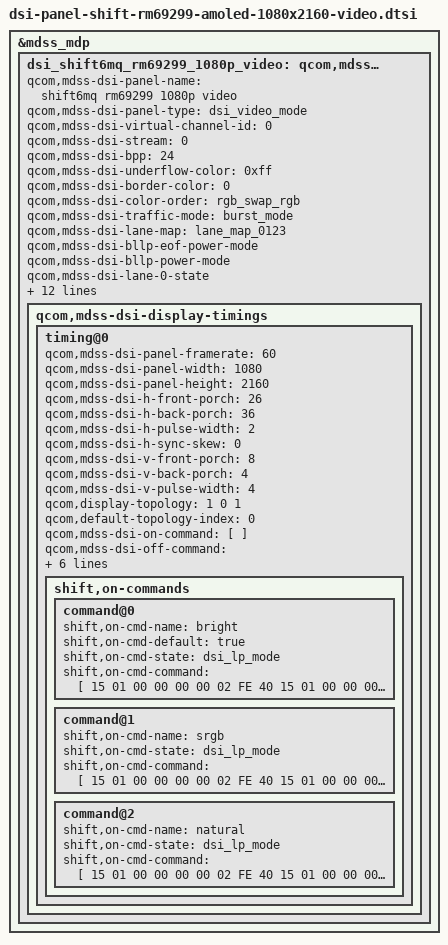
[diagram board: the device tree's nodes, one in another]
/* Copyright (c) 2016-2017, The Linux Foundation. All rights reserved.
 *
 * This program is free software; you can redistribute it and/or modify
 * it under the terms of the GNU General Public License version 2 and
 * only version 2 as published by the Free Software Foundation.
 *
 * This program is distributed in the hope that it will be useful,
 * but WITHOUT ANY WARRANTY; without even the implied warranty of
 * MERCHANTABILITY or FITNESS FOR A PARTICULAR PURPOSE.  See the
 * GNU General Public License for more details.
 */

&mdss_mdp {
	dsi_shift6mq_rm69299_1080p_video: qcom,mdss_dsi_shift6mq_rm69299_1080p_video {
		qcom,mdss-dsi-panel-name =
			"shift6mq rm69299 1080p video";
		qcom,mdss-dsi-panel-type = "dsi_video_mode";
		qcom,mdss-dsi-virtual-channel-id = <0>;
		qcom,mdss-dsi-stream = <0>;
		qcom,mdss-dsi-bpp = <24>;
                qcom,mdss-dsi-underflow-color = <0xff>;
		qcom,mdss-dsi-border-color = <0>;
		qcom,mdss-dsi-color-order = "rgb_swap_rgb"; 
		qcom,mdss-dsi-traffic-mode = "burst_mode";
		qcom,mdss-dsi-lane-map = "lane_map_0123"; 
		qcom,mdss-dsi-bllp-eof-power-mode;
		qcom,mdss-dsi-bllp-power-mode;
		qcom,mdss-dsi-lane-0-state;
		qcom,mdss-dsi-lane-1-state;
		qcom,mdss-dsi-lane-2-state;
		qcom,mdss-dsi-lane-3-state;
		qcom,mdss-dsi-force-clock-lane-hs;
		qcom,mdss-dsi-dma-trigger = "trigger_sw";
		qcom,mdss-dsi-mdp-trigger = "none";
                qcom,mdss-dsi-reset-sequence = <1 20>, <0 20>, <1 20>;
		qcom,mdss-pan-physical-width-dimension = <74>;
		qcom,mdss-pan-physical-height-dimension = <131>;
                qcom,mdss-dsi-t-clk-post = <0x0d>;  
                qcom,mdss-dsi-t-clk-pre = <0x2f>; 
		qcom,mdss-dsi-lp11-init; 
		qcom,mdss-dsi-display-timings {
			timing@0{
                                qcom,mdss-dsi-panel-framerate = <60>;
				qcom,mdss-dsi-panel-width = <1080>;
				qcom,mdss-dsi-panel-height = <2160>;
		                qcom,mdss-dsi-h-front-porch = <26>;
		                qcom,mdss-dsi-h-back-porch = <36>;
		                qcom,mdss-dsi-h-pulse-width = <2>;
				qcom,mdss-dsi-h-sync-skew = <0>;
		                qcom,mdss-dsi-v-front-porch = <8>;
		                qcom,mdss-dsi-v-back-porch = <4>;
		                qcom,mdss-dsi-v-pulse-width = <4>;
                                qcom,display-topology = <1 0 1>;
                                qcom,default-topology-index = <0>; 
				qcom,mdss-dsi-on-command = [
				];
				qcom,mdss-dsi-off-command = [05 01 00 00 14 00 02 28 00
			                                     05 01 00 00 78 00 02 10 00];
				qcom,mdss-dsi-on-command-state = "dsi_lp_mode";
				qcom,mdss-dsi-off-command-state = "dsi_hs_mode";  
				qcom,mdss-dsi-h-sync-pulse = <0>;
                                qcom,mdss-dsi-panel-phy-timings = [00 1e 08 08 24 22 08 08 05 03 04 00];
				shift,on-commands {
					command@0 {
						shift,on-cmd-name = "bright";
						shift,on-cmd-default = "true";
						shift,on-cmd-state = "dsi_lp_mode";
						shift,on-cmd-command = [
                                 15 01 00 00 00 00 02 FE 40 
                                 15 01 00 00 00 00 02 05 04 
                                 15 01 00 00 00 00 02 06 08 
                                 15 01 00 00 00 00 02 08 04 
                                 15 01 00 00 00 00 02 09 08           
                                 15 01 00 00 00 00 02 0A 07 
                                 15 01 00 00 00 00 02 0B CC 
                                 15 01 00 00 00 00 02 0C 07 
                                 15 01 00 00 00 00 02 0D 90 
                                 15 01 00 00 00 00 02 0F 87 
                                 15 01 00 00 00 00 02 20 8D 
                                 15 01 00 00 00 00 02 21 8D 
                                 15 01 00 00 00 00 02 24 05 
                                 15 01 00 00 00 00 02 26 05 
                                 15 01 00 00 00 00 02 28 05 
                                 15 01 00 00 00 00 02 2A 05 
                                 15 01 00 00 00 00 02 2D 28 
                                 15 01 00 00 00 00 02 2F 28 
                                 15 01 00 00 00 00 02 30 32 
                                 15 01 00 00 00 00 02 31 32 
                                 15 01 00 00 00 00 02 37 80 
                                 15 01 00 00 00 00 02 38 30 
                                 15 01 00 00 00 00 02 39 A8     
                                 15 01 00 00 00 00 02 46 48
                                 15 01 00 00 00 00 02 47 48 
                                 15 01 00 00 00 00 02 6B 10  
                                 15 01 00 00 00 00 02 6F 02 
                                 15 01 00 00 00 00 02 74 2B /* (AVDD) 7.6V*/
                                 15 01 00 00 00 00 02 80 1A /* (OVSS)  -2.9V*/
                                 15 01 00 00 00 00 02 FE 40 
                                 15 01 00 00 00 00 02 93 10 
                                 15 01 00 00 00 00 02 16 00 
                                 15 01 00 00 00 00 02 85 07 
                                 15 01 00 00 00 00 02 84 01 
                                 15 01 00 00 00 00 02 86 0F 
                                 15 01 00 00 00 00 02 87 05 
                                 15 01 00 00 00 00 02 8C 00 
                                 15 01 00 00 00 00 02 88 2E 
                                 15 01 00 00 00 00 02 89 2E 
                                 15 01 00 00 00 00 02 8B 09 
                                 15 01 00 00 00 00 02 95 00 
                                 15 01 00 00 00 00 02 91 00 
                                 15 01 00 00 00 00 02 90 00 
                                 15 01 00 00 00 00 02 8D D0 
                                 15 01 00 00 00 00 02 8A 03 
                                 15 01 00 00 00 00 02 FE A0 
                                 15 01 00 00 00 00 02 13 00 
                                 15 01 00 00 00 00 02 33 00 
                                 15 01 00 00 00 00 02 0B 33 
                                 15 01 00 00 00 00 02 36 1E 
                                 15 01 00 00 00 00 02 31 88 
                                 15 01 00 00 00 00 02 32 88 
                                 15 01 00 00 00 00 02 37 F1 
                                 15 01 00 00 00 00 02 FE 50
                                 15 01 00 00 00 00 02 00 00 //R0
                                 15 01 00 00 00 00 02 01 00
                                 15 01 00 00 00 00 02 02 00
                                 15 01 00 00 00 00 02 03 E9
                                 15 01 00 00 00 00 02 04 00
                                 15 01 00 00 00 00 02 05 F6
                                 15 01 00 00 00 00 02 06 01
                                 15 01 00 00 00 00 02 07 2C
                                 15 01 00 00 00 00 02 08 01
                                 15 01 00 00 00 00 02 09 62
                                 15 01 00 00 00 00 02 0A 01
                                 15 01 00 00 00 00 02 0B 98
                                 15 01 00 00 00 00 02 0C 01
                                 15 01 00 00 00 00 02 0D BF
                                 15 01 00 00 00 00 02 0E 01
                                 15 01 00 00 00 00 02 0F F6
                                 15 01 00 00 00 00 02 10 02
                                 15 01 00 00 00 00 02 11 24
                                 15 01 00 00 00 00 02 12 02
                                 15 01 00 00 00 00 02 13 4E
                                 15 01 00 00 00 00 02 14 02
                                 15 01 00 00 00 00 02 15 70
                                 15 01 00 00 00 00 02 16 02
                                 15 01 00 00 00 00 02 17 AF
                                 15 01 00 00 00 00 02 18 02
                                 15 01 00 00 00 00 02 19 E2
                                 15 01 00 00 00 00 02 1A 03
                                 15 01 00 00 00 00 02 1B 1F
                                 15 01 00 00 00 00 02 1C 03
                                 15 01 00 00 00 00 02 1D 52
                                 15 01 00 00 00 00 02 1E 03
                                 15 01 00 00 00 00 02 1F 82
                                 15 01 00 00 00 00 02 20 03
                                 15 01 00 00 00 00 02 21 B6
                                 15 01 00 00 00 00 02 22 03
                                 15 01 00 00 00 00 02 23 F0
                                 15 01 00 00 00 00 02 24 04
                                 15 01 00 00 00 00 02 25 1F
                                 15 01 00 00 00 00 02 26 04
                                 15 01 00 00 00 00 02 27 37
                                 15 01 00 00 00 00 02 28 04
                                 15 01 00 00 00 00 02 29 59
                                 15 01 00 00 00 00 02 2A 04
                                 15 01 00 00 00 00 02 2B 68
                                 15 01 00 00 00 00 02 30 04
                                 15 01 00 00 00 00 02 31 85
                                 15 01 00 00 00 00 02 32 04
                                 15 01 00 00 00 00 02 33 A2
                                 15 01 00 00 00 00 02 34 04
                                 15 01 00 00 00 00 02 35 BC
                                 15 01 00 00 00 00 02 36 04
                                 15 01 00 00 00 00 02 37 D8
                                 15 01 00 00 00 00 02 38 04
                                 15 01 00 00 00 00 02 39 F4
                                 15 01 00 00 00 00 02 3A 05
                                 15 01 00 00 00 00 02 3B 0E
                                 15 01 00 00 00 00 02 40 05
                                 15 01 00 00 00 00 02 41 13
                                 15 01 00 00 00 00 02 42 05
                                 15 01 00 00 00 00 02 43 1F
                                 15 01 00 00 00 00 02 44 05
                                 15 01 00 00 00 00 02 45 1F
                                 15 01 00 00 00 00 02 46 00 //G0
                                 15 01 00 00 00 00 02 47 00
                                 15 01 00 00 00 00 02 48 01
                                 15 01 00 00 00 00 02 49 43
                                 15 01 00 00 00 00 02 4A 01
                                 15 01 00 00 00 00 02 4B 4C
                                 15 01 00 00 00 00 02 4C 01
                                 15 01 00 00 00 00 02 4D 6F
                                 15 01 00 00 00 00 02 4E 01
                                 15 01 00 00 00 00 02 4F 92
                                 15 01 00 00 00 00 02 50 01
                                 15 01 00 00 00 00 02 51 B5
                                 15 01 00 00 00 00 02 52 01
                                 15 01 00 00 00 00 02 53 D4
                                 15 01 00 00 00 00 02 58 02
                                 15 01 00 00 00 00 02 59 06
                                 15 01 00 00 00 00 02 5A 02
                                 15 01 00 00 00 00 02 5B 33
                                 15 01 00 00 00 00 02 5C 02
                                 15 01 00 00 00 00 02 5D 59
                                 15 01 00 00 00 00 02 5E 02
                                 15 01 00 00 00 00 02 5F 7D
                                 15 01 00 00 00 00 02 60 02
                                 15 01 00 00 00 00 02 61 BD
                                 15 01 00 00 00 00 02 62 02
                                 15 01 00 00 00 00 02 63 F7
                                 15 01 00 00 00 00 02 64 03
                                 15 01 00 00 00 00 02 65 31
                                 15 01 00 00 00 00 02 66 03
                                 15 01 00 00 00 00 02 67 63
                                 15 01 00 00 00 00 02 68 03
                                 15 01 00 00 00 00 02 69 9D
                                 15 01 00 00 00 00 02 6A 03
                                 15 01 00 00 00 00 02 6B D2
                                 15 01 00 00 00 00 02 6C 04
                                 15 01 00 00 00 00 02 6D 05
                                 15 01 00 00 00 00 02 6E 04
                                 15 01 00 00 00 00 02 6F 38
                                 15 01 00 00 00 00 02 70 04
                                 15 01 00 00 00 00 02 71 51
                                 15 01 00 00 00 00 02 72 04
                                 15 01 00 00 00 00 02 73 70
                                 15 01 00 00 00 00 02 74 04
                                 15 01 00 00 00 00 02 75 85
                                 15 01 00 00 00 00 02 76 04
                                 15 01 00 00 00 00 02 77 A1
                                 15 01 00 00 00 00 02 78 04
                                 15 01 00 00 00 00 02 79 C0
                                 15 01 00 00 00 00 02 7A 04
                                 15 01 00 00 00 00 02 7B D8
                                 15 01 00 00 00 00 02 7C 04
                                 15 01 00 00 00 00 02 7D F2
                                 15 01 00 00 00 00 02 7E 05
                                 15 01 00 00 00 00 02 7F 10
                                 15 01 00 00 00 00 02 80 05
                                 15 01 00 00 00 00 02 81 21
                                 15 01 00 00 00 00 02 82 05
                                 15 01 00 00 00 00 02 83 2E
                                 15 01 00 00 00 00 02 84 05
                                 15 01 00 00 00 00 02 85 3A
                                 15 01 00 00 00 00 02 86 05
                                 15 01 00 00 00 00 02 87 3E
                                 15 01 00 00 00 00 02 88 00 //B0
                                 15 01 00 00 00 00 02 89 00
                                 15 01 00 00 00 00 02 8A 01
                                 15 01 00 00 00 00 02 8B 86
                                 15 01 00 00 00 00 02 8C 01
                                 15 01 00 00 00 00 02 8D 8F
                                 15 01 00 00 00 00 02 8E 01
                                 15 01 00 00 00 00 02 8F B3
                                 15 01 00 00 00 00 02 90 01
                                 15 01 00 00 00 00 02 91 D7
                                 15 01 00 00 00 00 02 92 01
                                 15 01 00 00 00 00 02 93 FB
                                 15 01 00 00 00 00 02 94 02
                                 15 01 00 00 00 00 02 95 18
                                 15 01 00 00 00 00 02 96 02
                                 15 01 00 00 00 00 02 97 4F
                                 15 01 00 00 00 00 02 98 02
                                 15 01 00 00 00 00 02 99 7E
                                 15 01 00 00 00 00 02 9A 02
                                 15 01 00 00 00 00 02 9B A6
                                 15 01 00 00 00 00 02 9C 02
                                 15 01 00 00 00 00 02 9D CF
                                 15 01 00 00 00 00 02 9E 03
                                 15 01 00 00 00 00 02 9F 14
                                 15 01 00 00 00 00 02 A4 03
                                 15 01 00 00 00 00 02 A5 52
                                 15 01 00 00 00 00 02 A6 03
                                 15 01 00 00 00 00 02 A7 93
                                 15 01 00 00 00 00 02 AC 03
                                 15 01 00 00 00 00 02 AD CF
                                 15 01 00 00 00 00 02 AE 04
                                 15 01 00 00 00 00 02 AF 08
                                 15 01 00 00 00 00 02 B0 04
                                 15 01 00 00 00 00 02 B1 42
                                 15 01 00 00 00 00 02 B2 04
                                 15 01 00 00 00 00 02 B3 7F
                                 15 01 00 00 00 00 02 B4 04
                                 15 01 00 00 00 00 02 B5 B4
                                 15 01 00 00 00 00 02 B6 04
                                 15 01 00 00 00 00 02 B7 CC
                                 15 01 00 00 00 00 02 B8 04
                                 15 01 00 00 00 00 02 B9 F2
                                 15 01 00 00 00 00 02 BA 05
                                 15 01 00 00 00 00 02 BB 0C
                                 15 01 00 00 00 00 02 BC 05
                                 15 01 00 00 00 00 02 BD 26
                                 15 01 00 00 00 00 02 BE 05
                                 15 01 00 00 00 00 02 BF 4B
                                 15 01 00 00 00 00 02 C0 05
                                 15 01 00 00 00 00 02 C1 64
                                 15 01 00 00 00 00 02 C2 05
                                 15 01 00 00 00 00 02 C3 83
                                 15 01 00 00 00 00 02 C4 05
                                 15 01 00 00 00 00 02 C5 A1
                                 15 01 00 00 00 00 02 C6 05
                                 15 01 00 00 00 00 02 C7 BA
                                 15 01 00 00 00 00 02 C8 05
                                 15 01 00 00 00 00 02 C9 C4
                                 15 01 00 00 00 00 02 CA 05
                                 15 01 00 00 00 00 02 CB D5
                                 15 01 00 00 00 00 02 CC 05
                                 15 01 00 00 00 00 02 CD D5
                                 15 01 00 00 00 00 02 CE 00
                                 15 01 00 00 00 00 02 CF CE
                                 15 01 00 00 00 00 02 D0 00
                                 15 01 00 00 00 00 02 D1 DB
                                 15 01 00 00 00 00 02 D2 01
                                 15 01 00 00 00 00 02 D3 32
                                 15 01 00 00 00 00 02 D4 01
                                 15 01 00 00 00 00 02 D5 3B
                                 15 01 00 00 00 00 02 D6 01
                                 15 01 00 00 00 00 02 D7 74
                                 15 01 00 00 00 00 02 D8 01
                                 15 01 00 00 00 00 02 D9 7D
                                 15 01 00 00 00 00 02 FE 60 
                                 15 01 00 00 00 00 02 00 CC 
                                 15 01 00 00 00 00 02 01 0F 
                                 15 01 00 00 00 00 02 02 FF 
                                 15 01 00 00 00 00 02 03 01 
                                 15 01 00 00 00 00 02 04 00 
                                 15 01 00 00 00 00 02 05 02 
                                 15 01 00 00 00 00 02 06 00 
                                 15 01 00 00 00 00 02 07 00 
                                 15 01 00 00 00 00 02 09 C4 
                                 15 01 00 00 00 00 02 0A 00 
                                 15 01 00 00 00 00 02 0B 04 
                                 15 01 00 00 00 00 02 0C 01 
                                 15 01 00 00 00 00 02 0D 00 
                                 15 01 00 00 00 00 02 0E 04 
                                 15 01 00 00 00 00 02 0F 00 
                                 15 01 00 00 00 00 02 10 71 
                                 15 01 00 00 00 00 02 12 C4 
                                 15 01 00 00 00 00 02 13 00 
                                 15 01 00 00 00 00 02 14 04 
                                 15 01 00 00 00 00 02 15 01 
                                 15 01 00 00 00 00 02 16 00 
                                 15 01 00 00 00 00 02 17 06 
                                 15 01 00 00 00 00 02 18 00 
                                 15 01 00 00 00 00 02 19 71 
                                 15 01 00 00 00 00 02 1B C4 
                                 15 01 00 00 00 00 02 1C 00 
                                 15 01 00 00 00 00 02 1D 02 
                                 15 01 00 00 00 00 02 1E 00 
                                 15 01 00 00 00 00 02 1F 00 
                                 15 01 00 00 00 00 02 20 08 
                                 15 01 00 00 00 00 02 21 66 
                                 15 01 00 00 00 00 02 22 B4 
                                 15 01 00 00 00 00 02 24 C4 
                                 15 01 00 00 00 00 02 25 00 
                                 15 01 00 00 00 00 02 26 02 
                                 15 01 00 00 00 00 02 27 00 
                                 15 01 00 00 00 00 02 28 00 
                                 15 01 00 00 00 00 02 29 07 
                                 15 01 00 00 00 00 02 2A 66 
                                 15 01 00 00 00 00 02 2B B4 
                                 15 01 00 00 00 00 02 2F C4 
                                 15 01 00 00 00 00 02 30 00 
                                 15 01 00 00 00 00 02 31 04 
                                 15 01 00 00 00 00 02 32 01 
                                 15 01 00 00 00 00 02 33 00 
                                 15 01 00 00 00 00 02 34 03 
                                 15 01 00 00 00 00 02 35 00 
                                 15 01 00 00 00 00 02 36 71 
                                 15 01 00 00 00 00 02 38 C4 
                                 15 01 00 00 00 00 02 39 00 
                                 15 01 00 00 00 00 02 3A 04 
                                 15 01 00 00 00 00 02 3B 01 
                                 15 01 00 00 00 00 02 3D 00 
                                 15 01 00 00 00 00 02 3F 05 
                                 15 01 00 00 00 00 02 40 00 
                                 15 01 00 00 00 00 02 41 71 
                                 15 01 00 00 00 00 02 83 CE 
                                 15 01 00 00 00 00 02 84 02 
                                 15 01 00 00 00 00 02 85 20 
                                 15 01 00 00 00 00 02 86 DC 
                                 15 01 00 00 00 00 02 87 00 
                                 15 01 00 00 00 00 02 88 04 
                                 15 01 00 00 00 00 02 89 00 
                                 15 01 00 00 00 00 02 8A BB 
                                 15 01 00 00 00 00 02 8B 80 
                                 15 01 00 00 00 00 02 C7 0E  
                                 15 01 00 00 00 00 02 C8 05 
                                 15 01 00 00 00 00 02 C9 1F 
                                 15 01 00 00 00 00 02 CA 06 
                                 15 01 00 00 00 00 02 CB 00 
                                 15 01 00 00 00 00 02 CC 03 
                                 15 01 00 00 00 00 02 CD 04 
                                 15 01 00 00 00 00 02 CE 1F 
                                 15 01 00 00 00 00 02 CF 1F 
                                 15 01 00 00 00 00 02 D0 1F 
                                 15 01 00 00 00 00 02 D1 1F 
                                 15 01 00 00 00 00 02 D2 1F 
                                 15 01 00 00 00 00 02 D3 1F 
                                 15 01 00 00 00 00 02 D4 1F 
                                 15 01 00 00 00 00 02 D5 1F 
                                 15 01 00 00 00 00 02 D6 1F 
                                 15 01 00 00 00 00 02 D7 17 
                                 15 01 00 00 00 00 02 D8 1F 
                                 15 01 00 00 00 00 02 D9 16 
                                 15 01 00 00 00 00 02 DA 1F 
                                 15 01 00 00 00 00 02 DB 0E  
                                 15 01 00 00 00 00 02 DC 01 
                                 15 01 00 00 00 00 02 DD 1F 
                                 15 01 00 00 00 00 02 DE 02 
                                 15 01 00 00 00 00 02 DF 00 
                                 15 01 00 00 00 00 02 E0 03 
                                 15 01 00 00 00 00 02 E1 04 
                                 15 01 00 00 00 00 02 E2 1F 
                                 15 01 00 00 00 00 02 E3 1F 
                                 15 01 00 00 00 00 02 E4 1F 
                                 15 01 00 00 00 00 02 E5 1F 
                                 15 01 00 00 00 00 02 E6 1F 
                                 15 01 00 00 00 00 02 E7 1F 
                                 15 01 00 00 00 00 02 E8 1F 
                                 15 01 00 00 00 00 02 E9 1F 
                                 15 01 00 00 00 00 02 EA 1F 
                                 15 01 00 00 00 00 02 EB 17    
                                 15 01 00 00 00 00 02 EC 1F 
                                 15 01 00 00 00 00 02 ED 16 
                                 15 01 00 00 00 00 02 EE 1F 
                                 15 01 00 00 00 00 02 EF 03 
                                 15 01 00 00 00 00 02 FE 70 
                                 15 01 00 00 00 00 02 5A 0B 
                                 15 01 00 00 00 00 02 5B 0B 
                                 15 01 00 00 00 00 02 5C 55 
                                 15 01 00 00 00 00 02 5D 24                         
                                 15 01 00 00 00 00 02 FE 90 
                                 15 01 00 00 00 00 02 12 24 
                                 15 01 00 00 00 00 02 13 49 
                                 15 01 00 00 00 00 02 14 92 
                                 15 01 00 00 00 00 02 15 86 
                                 15 01 00 00 00 00 02 16 61 
                                 15 01 00 00 00 00 02 17 18 
                                 15 01 00 00 00 00 02 18 24 
                                 15 01 00 00 00 00 02 19 49 
                                 15 01 00 00 00 00 02 1A 92 
                                 15 01 00 00 00 00 02 1B 86 
                                 15 01 00 00 00 00 02 1C 61 
                                 15 01 00 00 00 00 02 1D 18 
                                 15 01 00 00 00 00 02 1E 24 
                                 15 01 00 00 00 00 02 1F 49 
                                 15 01 00 00 00 00 02 20 92 
                                 15 01 00 00 00 00 02 21 86 
                                 15 01 00 00 00 00 02 22 61 
                                 15 01 00 00 00 00 02 23 18 
                                 15 01 00 00 00 00 02 FE 40 
                                 15 01 00 00 00 00 02 0E 10 
                                 15 01 00 00 00 00 02 FE A0
                                 15 01 00 00 00 00 02 04 80
                                 15 01 00 00 00 00 02 16 00
                                 15 01 00 00 00 00 02 26 10
                                 15 01 00 00 00 00 02 2F 37    
                                 15 01 00 00 00 00 02 FE D0
                                 15 01 00 00 00 00 02 06 0F
                                 15 01 00 00 00 00 02 4B 00
                                 15 01 00 00 00 00 02 56 4A
                                 15 01 00 00 00 00 02 FE 00 
                                 15 01 00 00 00 00 02 C2 09 /*08 command  09 video*/
                                 15 01 00 00 00 00 02 35 00 
                                 15 01 00 00 00 00 02 FE 70 
                                 15 01 00 00 00 00 02 7D 61 
                                 15 01 00 00 00 00 02 7F 00 /*40:10bit 00 8bit*/
                                 15 01 00 00 00 00 02 7E 4E 
                                 15 01 00 00 00 00 02 52 2C 
                                 15 01 00 00 00 00 02 49 00 
                                 15 01 00 00 00 00 02 4A 00 
                                 15 01 00 00 00 00 02 4B 00 
                                 15 01 00 00 00 00 02 4C 00 
                                 15 01 00 00 00 00 02 4D E8 
                                 15 01 00 00 00 00 02 4E 25 
                                 15 01 00 00 00 00 02 4F 6E 
                                 15 01 00 00 00 00 02 50 AE 
                                 15 01 00 00 00 00 02 51 2F 
                                 15 01 00 00 00 00 02 AD F4 
                                 15 01 00 00 00 00 02 AE 8F 
                                 15 01 00 00 00 00 02 AF 00 
                                 15 01 00 00 00 00 02 B0 54 
                                 15 01 00 00 00 00 02 B1 3A      
                                 15 01 00 00 00 00 02 B2 00 
                                 15 01 00 00 00 00 02 B3 00 
                                 15 01 00 00 00 00 02 B4 00 
                                 15 01 00 00 00 00 02 B5 00 
                                 15 01 00 00 00 00 02 B6 18 
                                 15 01 00 00 00 00 02 B7 30 
                                 15 01 00 00 00 00 02 B8 4A 
                                 15 01 00 00 00 00 02 B9 98 
                                 15 01 00 00 00 00 02 BA 30 
                                 15 01 00 00 00 00 02 BB 60 
                                 15 01 00 00 00 00 02 BC 50 
                                 15 01 00 00 00 00 02 BD 00                            
                                 15 01 00 00 00 00 02 BE 00                            
                                 15 01 00 00 00 00 02 BF 39
                                 15 01 00 00 00 00 02 FE 00                            
                                 15 01 00 00 00 00 02 51 66   
				 05 01 00 00 78 00 02 11 00
				 05 01 00 00 14 00 02 29 00
						];
					};

					command@1 {
						shift,on-cmd-name = "srgb";
						shift,on-cmd-state = "dsi_lp_mode";
						shift,on-cmd-command = [
                                 15 01 00 00 00 00 02 FE 40 
                                 15 01 00 00 00 00 02 05 04 
                                 15 01 00 00 00 00 02 06 08 
                                 15 01 00 00 00 00 02 08 04 
                                 15 01 00 00 00 00 02 09 08           
                                 15 01 00 00 00 00 02 0A 07 
                                 15 01 00 00 00 00 02 0B CC 
                                 15 01 00 00 00 00 02 0C 07 
                                 15 01 00 00 00 00 02 0D 90 
                                 15 01 00 00 00 00 02 0F 87 
                                 15 01 00 00 00 00 02 20 8D 
                                 15 01 00 00 00 00 02 21 8D 
                                 15 01 00 00 00 00 02 24 05 
                                 15 01 00 00 00 00 02 26 05 
                                 15 01 00 00 00 00 02 28 05 
                                 15 01 00 00 00 00 02 2A 05 
                                 15 01 00 00 00 00 02 2D 28 
                                 15 01 00 00 00 00 02 2F 28 
                                 15 01 00 00 00 00 02 30 32 
                                 15 01 00 00 00 00 02 31 32 
                                 15 01 00 00 00 00 02 37 80 
                                 15 01 00 00 00 00 02 38 30 
                                 15 01 00 00 00 00 02 39 A8     
                                 15 01 00 00 00 00 02 46 48
                                 15 01 00 00 00 00 02 47 48 
                                 15 01 00 00 00 00 02 6B 10  
                                 15 01 00 00 00 00 02 6F 02 
                                 15 01 00 00 00 00 02 74 2B /* (AVDD) 7.6V*/
                                 15 01 00 00 00 00 02 80 1A /* (OVSS)  -2.9V*/
                                 15 01 00 00 00 00 02 FE 40 
                                 15 01 00 00 00 00 02 93 10 
                                 15 01 00 00 00 00 02 16 00 
                                 15 01 00 00 00 00 02 85 07 
                                 15 01 00 00 00 00 02 84 01 
                                 15 01 00 00 00 00 02 86 0F 
                                 15 01 00 00 00 00 02 87 05 
                                 15 01 00 00 00 00 02 8C 00 
                                 15 01 00 00 00 00 02 88 2E 
                                 15 01 00 00 00 00 02 89 2E 
                                 15 01 00 00 00 00 02 8B 09 
                                 15 01 00 00 00 00 02 95 00 
                                 15 01 00 00 00 00 02 91 00 
                                 15 01 00 00 00 00 02 90 00 
                                 15 01 00 00 00 00 02 8D D0 
                                 15 01 00 00 00 00 02 8A 03 
                                 15 01 00 00 00 00 02 FE A0 
                                 15 01 00 00 00 00 02 13 00 
                                 15 01 00 00 00 00 02 33 00 
                                 15 01 00 00 00 00 02 0B 33 
                                 15 01 00 00 00 00 02 36 1E 
                                 15 01 00 00 00 00 02 31 88 
                                 15 01 00 00 00 00 02 32 88 
                                 15 01 00 00 00 00 02 37 F1 
                                 15 01 00 00 00 00 02 FE 50
                                 15 01 00 00 00 00 02 00 00 //R0
                                 15 01 00 00 00 00 02 01 00
                                 15 01 00 00 00 00 02 02 00
                                 15 01 00 00 00 00 02 03 EA
                                 15 01 00 00 00 00 02 04 00
                                 15 01 00 00 00 00 02 05 F7
                                 15 01 00 00 00 00 02 06 01
                                 15 01 00 00 00 00 02 07 2D
                                 15 01 00 00 00 00 02 08 01
                                 15 01 00 00 00 00 02 09 63
                                 15 01 00 00 00 00 02 0A 01
                                 15 01 00 00 00 00 02 0B 99
                                 15 01 00 00 00 00 02 0C 01
                                 15 01 00 00 00 00 02 0D BF
                                 15 01 00 00 00 00 02 0E 01
                                 15 01 00 00 00 00 02 0F F6
                                 15 01 00 00 00 00 02 10 02
                                 15 01 00 00 00 00 02 11 24
                                 15 01 00 00 00 00 02 12 02
                                 15 01 00 00 00 00 02 13 4E
                                 15 01 00 00 00 00 02 14 02
                                 15 01 00 00 00 00 02 15 70
                                 15 01 00 00 00 00 02 16 02
                                 15 01 00 00 00 00 02 17 AF
                                 15 01 00 00 00 00 02 18 02
                                 15 01 00 00 00 00 02 19 E7
                                 15 01 00 00 00 00 02 1A 03
                                 15 01 00 00 00 00 02 1B 1D
                                 15 01 00 00 00 00 02 1C 03
                                 15 01 00 00 00 00 02 1D 52
                                 15 01 00 00 00 00 02 1E 03
                                 15 01 00 00 00 00 02 1F 85
                                 15 01 00 00 00 00 02 20 03
                                 15 01 00 00 00 00 02 21 BA
                                 15 01 00 00 00 00 02 22 03
                                 15 01 00 00 00 00 02 23 E6
                                 15 01 00 00 00 00 02 24 04
                                 15 01 00 00 00 00 02 25 1B
                                 15 01 00 00 00 00 02 26 04
                                 15 01 00 00 00 00 02 27 36
                                 15 01 00 00 00 00 02 28 04
                                 15 01 00 00 00 00 02 29 50
                                 15 01 00 00 00 00 02 2A 04
                                 15 01 00 00 00 00 02 2B 69
                                 15 01 00 00 00 00 02 30 04
                                 15 01 00 00 00 00 02 31 86
                                 15 01 00 00 00 00 02 32 04
                                 15 01 00 00 00 00 02 33 A4
                                 15 01 00 00 00 00 02 34 04
                                 15 01 00 00 00 00 02 35 BF
                                 15 01 00 00 00 00 02 36 04
                                 15 01 00 00 00 00 02 37 D6
                                 15 01 00 00 00 00 02 38 04
                                 15 01 00 00 00 00 02 39 F9
                                 15 01 00 00 00 00 02 3A 05
                                 15 01 00 00 00 00 02 3B 04
                                 15 01 00 00 00 00 02 40 05
                                 15 01 00 00 00 00 02 41 17
                                 15 01 00 00 00 00 02 42 05
                                 15 01 00 00 00 00 02 43 18
                                 15 01 00 00 00 00 02 44 05
                                 15 01 00 00 00 00 02 45 18
                                 15 01 00 00 00 00 02 46 00 //G0
                                 15 01 00 00 00 00 02 47 00
                                 15 01 00 00 00 00 02 48 01
                                 15 01 00 00 00 00 02 49 45
                                 15 01 00 00 00 00 02 4A 01
                                 15 01 00 00 00 00 02 4B 4D
                                 15 01 00 00 00 00 02 4C 01
                                 15 01 00 00 00 00 02 4D 6F
                                 15 01 00 00 00 00 02 4E 01
                                 15 01 00 00 00 00 02 4F 91
                                 15 01 00 00 00 00 02 50 01
                                 15 01 00 00 00 00 02 51 B3
                                 15 01 00 00 00 00 02 52 01
                                 15 01 00 00 00 00 02 53 D1
                                 15 01 00 00 00 00 02 58 02
                                 15 01 00 00 00 00 02 59 03
                                 15 01 00 00 00 00 02 5A 02
                                 15 01 00 00 00 00 02 5B 2F
                                 15 01 00 00 00 00 02 5C 02
                                 15 01 00 00 00 00 02 5D 54
                                 15 01 00 00 00 00 02 5E 02
                                 15 01 00 00 00 00 02 5F 77
                                 15 01 00 00 00 00 02 60 02
                                 15 01 00 00 00 00 02 61 BA
                                 15 01 00 00 00 00 02 62 02
                                 15 01 00 00 00 00 02 63 F3
                                 15 01 00 00 00 00 02 64 03
                                 15 01 00 00 00 00 02 65 2C
                                 15 01 00 00 00 00 02 66 03
                                 15 01 00 00 00 00 02 67 61
                                 15 01 00 00 00 00 02 68 03
                                 15 01 00 00 00 00 02 69 93
                                 15 01 00 00 00 00 02 6A 03
                                 15 01 00 00 00 00 02 6B C9
                                 15 01 00 00 00 00 02 6C 03
                                 15 01 00 00 00 00 02 6D FA
                                 15 01 00 00 00 00 02 6E 04
                                 15 01 00 00 00 00 02 6F 30
                                 15 01 00 00 00 00 02 70 04
                                 15 01 00 00 00 00 02 71 4A
                                 15 01 00 00 00 00 02 72 04
                                 15 01 00 00 00 00 02 73 61
                                 15 01 00 00 00 00 02 74 04
                                 15 01 00 00 00 00 02 75 7D
                                 15 01 00 00 00 00 02 76 04
                                 15 01 00 00 00 00 02 77 97
                                 15 01 00 00 00 00 02 78 04
                                 15 01 00 00 00 00 02 79 B2
                                 15 01 00 00 00 00 02 7A 04
                                 15 01 00 00 00 00 02 7B D0
                                 15 01 00 00 00 00 02 7C 04
                                 15 01 00 00 00 00 02 7D ED
                                 15 01 00 00 00 00 02 7E 05
                                 15 01 00 00 00 00 02 7F 05
                                 15 01 00 00 00 00 02 80 05
                                 15 01 00 00 00 00 02 81 14
                                 15 01 00 00 00 00 02 82 05
                                 15 01 00 00 00 00 02 83 29
                                 15 01 00 00 00 00 02 84 05
                                 15 01 00 00 00 00 02 85 2E
                                 15 01 00 00 00 00 02 86 05
                                 15 01 00 00 00 00 02 87 2F
                                 15 01 00 00 00 00 02 88 00 //B0
                                 15 01 00 00 00 00 02 89 00
                                 15 01 00 00 00 00 02 8A 01
                                 15 01 00 00 00 00 02 8B 86
                                 15 01 00 00 00 00 02 8C 01
                                 15 01 00 00 00 00 02 8D 8F
                                 15 01 00 00 00 00 02 8E 01
                                 15 01 00 00 00 00 02 8F B3
                                 15 01 00 00 00 00 02 90 01
                                 15 01 00 00 00 00 02 91 D7
                                 15 01 00 00 00 00 02 92 01
                                 15 01 00 00 00 00 02 93 FB
                                 15 01 00 00 00 00 02 94 02
                                 15 01 00 00 00 00 02 95 18
                                 15 01 00 00 00 00 02 96 02
                                 15 01 00 00 00 00 02 97 4E
                                 15 01 00 00 00 00 02 98 02
                                 15 01 00 00 00 00 02 99 7C
                                 15 01 00 00 00 00 02 9A 02
                                 15 01 00 00 00 00 02 9B A6
                                 15 01 00 00 00 00 02 9C 02
                                 15 01 00 00 00 00 02 9D CF
                                 15 01 00 00 00 00 02 9E 03
                                 15 01 00 00 00 00 02 9F 14
                                 15 01 00 00 00 00 02 A4 03
                                 15 01 00 00 00 00 02 A5 56
                                 15 01 00 00 00 00 02 A6 03
                                 15 01 00 00 00 00 02 A7 92
                                 15 01 00 00 00 00 02 AC 03
                                 15 01 00 00 00 00 02 AD CF
                                 15 01 00 00 00 00 02 AE 04
                                 15 01 00 00 00 00 02 AF 08
                                 15 01 00 00 00 00 02 B0 04
                                 15 01 00 00 00 00 02 B1 44
                                 15 01 00 00 00 00 02 B2 04
                                 15 01 00 00 00 00 02 B3 76
                                 15 01 00 00 00 00 02 B4 04
                                 15 01 00 00 00 00 02 B5 B2
                                 15 01 00 00 00 00 02 B6 04
                                 15 01 00 00 00 00 02 B7 D1
                                 15 01 00 00 00 00 02 B8 04
                                 15 01 00 00 00 00 02 B9 EC
                                 15 01 00 00 00 00 02 BA 05
                                 15 01 00 00 00 00 02 BB 08
                                 15 01 00 00 00 00 02 BC 05
                                 15 01 00 00 00 00 02 BD 25
                                 15 01 00 00 00 00 02 BE 05
                                 15 01 00 00 00 00 02 BF 47
                                 15 01 00 00 00 00 02 C0 05
                                 15 01 00 00 00 00 02 C1 62
                                 15 01 00 00 00 00 02 C2 05
                                 15 01 00 00 00 00 02 C3 83
                                 15 01 00 00 00 00 02 C4 05
                                 15 01 00 00 00 00 02 C5 A2
                                 15 01 00 00 00 00 02 C6 05
                                 15 01 00 00 00 00 02 C7 B6
                                 15 01 00 00 00 00 02 C8 05
                                 15 01 00 00 00 00 02 C9 CE
                                 15 01 00 00 00 00 02 CA 05
                                 15 01 00 00 00 00 02 CB CF
                                 15 01 00 00 00 00 02 CC 05
                                 15 01 00 00 00 00 02 CD CF
                                 15 01 00 00 00 00 02 CE 00
                                 15 01 00 00 00 00 02 CF CF
                                 15 01 00 00 00 00 02 D0 00
                                 15 01 00 00 00 00 02 D1 DC
                                 15 01 00 00 00 00 02 D2 01
                                 15 01 00 00 00 00 02 D3 34
                                 15 01 00 00 00 00 02 D4 01
                                 15 01 00 00 00 00 02 D5 3C
                                 15 01 00 00 00 00 02 D6 01
                                 15 01 00 00 00 00 02 D7 74
                                 15 01 00 00 00 00 02 D8 01
                                 15 01 00 00 00 00 02 D9 7D
                                 15 01 00 00 00 00 02 FE 60 
                                 15 01 00 00 00 00 02 00 CC 
                                 15 01 00 00 00 00 02 01 0F 
                                 15 01 00 00 00 00 02 02 FF 
                                 15 01 00 00 00 00 02 03 01 
                                 15 01 00 00 00 00 02 04 00 
                                 15 01 00 00 00 00 02 05 02 
                                 15 01 00 00 00 00 02 06 00 
                                 15 01 00 00 00 00 02 07 00 
                                 15 01 00 00 00 00 02 09 C4 
                                 15 01 00 00 00 00 02 0A 00 
                                 15 01 00 00 00 00 02 0B 04 
                                 15 01 00 00 00 00 02 0C 01 
                                 15 01 00 00 00 00 02 0D 00 
                                 15 01 00 00 00 00 02 0E 04 
                                 15 01 00 00 00 00 02 0F 00 
                                 15 01 00 00 00 00 02 10 71 
                                 15 01 00 00 00 00 02 12 C4 
                                 15 01 00 00 00 00 02 13 00 
                                 15 01 00 00 00 00 02 14 04 
                                 15 01 00 00 00 00 02 15 01 
                                 15 01 00 00 00 00 02 16 00 
                                 15 01 00 00 00 00 02 17 06 
                                 15 01 00 00 00 00 02 18 00 
                                 15 01 00 00 00 00 02 19 71 
                                 15 01 00 00 00 00 02 1B C4 
                                 15 01 00 00 00 00 02 1C 00 
                                 15 01 00 00 00 00 02 1D 02 
                                 15 01 00 00 00 00 02 1E 00 
                                 15 01 00 00 00 00 02 1F 00 
                                 15 01 00 00 00 00 02 20 08 
                                 15 01 00 00 00 00 02 21 66 
                                 15 01 00 00 00 00 02 22 B4 
                                 15 01 00 00 00 00 02 24 C4 
                                 15 01 00 00 00 00 02 25 00 
                                 15 01 00 00 00 00 02 26 02 
                                 15 01 00 00 00 00 02 27 00 
                                 15 01 00 00 00 00 02 28 00 
                                 15 01 00 00 00 00 02 29 07 
                                 15 01 00 00 00 00 02 2A 66 
                                 15 01 00 00 00 00 02 2B B4 
                                 15 01 00 00 00 00 02 2F C4 
                                 15 01 00 00 00 00 02 30 00 
                                 15 01 00 00 00 00 02 31 04 
                                 15 01 00 00 00 00 02 32 01 
                                 15 01 00 00 00 00 02 33 00 
                                 15 01 00 00 00 00 02 34 03 
                                 15 01 00 00 00 00 02 35 00 
                                 15 01 00 00 00 00 02 36 71 
                                 15 01 00 00 00 00 02 38 C4 
                                 15 01 00 00 00 00 02 39 00 
                                 15 01 00 00 00 00 02 3A 04 
                                 15 01 00 00 00 00 02 3B 01 
                                 15 01 00 00 00 00 02 3D 00 
                                 15 01 00 00 00 00 02 3F 05 
                                 15 01 00 00 00 00 02 40 00 
                                 15 01 00 00 00 00 02 41 71 
                                 15 01 00 00 00 00 02 83 CE 
                                 15 01 00 00 00 00 02 84 02 
                                 15 01 00 00 00 00 02 85 20 
                                 15 01 00 00 00 00 02 86 DC 
                                 15 01 00 00 00 00 02 87 00 
                                 15 01 00 00 00 00 02 88 04 
                                 15 01 00 00 00 00 02 89 00 
                                 15 01 00 00 00 00 02 8A BB 
                                 15 01 00 00 00 00 02 8B 80 
                                 15 01 00 00 00 00 02 C7 0E  
                                 15 01 00 00 00 00 02 C8 05 
                                 15 01 00 00 00 00 02 C9 1F 
                                 15 01 00 00 00 00 02 CA 06 
                                 15 01 00 00 00 00 02 CB 00 
                                 15 01 00 00 00 00 02 CC 03 
                                 15 01 00 00 00 00 02 CD 04 
                                 15 01 00 00 00 00 02 CE 1F 
                                 15 01 00 00 00 00 02 CF 1F 
                                 15 01 00 00 00 00 02 D0 1F 
                                 15 01 00 00 00 00 02 D1 1F 
                                 15 01 00 00 00 00 02 D2 1F 
                                 15 01 00 00 00 00 02 D3 1F 
                                 15 01 00 00 00 00 02 D4 1F 
                                 15 01 00 00 00 00 02 D5 1F 
                                 15 01 00 00 00 00 02 D6 1F 
                                 15 01 00 00 00 00 02 D7 17 
                                 15 01 00 00 00 00 02 D8 1F 
                                 15 01 00 00 00 00 02 D9 16 
                                 15 01 00 00 00 00 02 DA 1F 
                                 15 01 00 00 00 00 02 DB 0E  
                                 15 01 00 00 00 00 02 DC 01 
                                 15 01 00 00 00 00 02 DD 1F 
                                 15 01 00 00 00 00 02 DE 02 
                                 15 01 00 00 00 00 02 DF 00 
                                 15 01 00 00 00 00 02 E0 03 
                                 15 01 00 00 00 00 02 E1 04 
                                 15 01 00 00 00 00 02 E2 1F 
                                 15 01 00 00 00 00 02 E3 1F 
                                 15 01 00 00 00 00 02 E4 1F 
                                 15 01 00 00 00 00 02 E5 1F 
                                 15 01 00 00 00 00 02 E6 1F 
                                 15 01 00 00 00 00 02 E7 1F 
                                 15 01 00 00 00 00 02 E8 1F 
                                 15 01 00 00 00 00 02 E9 1F 
                                 15 01 00 00 00 00 02 EA 1F 
                                 15 01 00 00 00 00 02 EB 17    
                                 15 01 00 00 00 00 02 EC 1F 
                                 15 01 00 00 00 00 02 ED 16 
                                 15 01 00 00 00 00 02 EE 1F 
                                 15 01 00 00 00 00 02 EF 03 
                                 15 01 00 00 00 00 02 FE 70 
                                 15 01 00 00 00 00 02 5A 0B 
                                 15 01 00 00 00 00 02 5B 0B 
                                 15 01 00 00 00 00 02 5C 55 
                                 15 01 00 00 00 00 02 5D 24                         
                                 15 01 00 00 00 00 02 FE 90 
                                 15 01 00 00 00 00 02 12 24 
                                 15 01 00 00 00 00 02 13 49 
                                 15 01 00 00 00 00 02 14 92 
                                 15 01 00 00 00 00 02 15 86 
                                 15 01 00 00 00 00 02 16 61 
                                 15 01 00 00 00 00 02 17 18 
                                 15 01 00 00 00 00 02 18 24 
                                 15 01 00 00 00 00 02 19 49 
                                 15 01 00 00 00 00 02 1A 92 
                                 15 01 00 00 00 00 02 1B 86 
                                 15 01 00 00 00 00 02 1C 61 
                                 15 01 00 00 00 00 02 1D 18 
                                 15 01 00 00 00 00 02 1E 24 
                                 15 01 00 00 00 00 02 1F 49 
                                 15 01 00 00 00 00 02 20 92 
                                 15 01 00 00 00 00 02 21 86 
                                 15 01 00 00 00 00 02 22 61 
                                 15 01 00 00 00 00 02 23 18 
                                 15 01 00 00 00 00 02 FE 40 
                                 15 01 00 00 00 00 02 0E 10 
                                 15 01 00 00 00 00 02 FE A0
                                 15 01 00 00 00 00 02 04 80
                                 15 01 00 00 00 00 02 16 00
                                 15 01 00 00 00 00 02 26 10
                                 15 01 00 00 00 00 02 2F 37    
                                 15 01 00 00 00 00 02 FE D0
                                 15 01 00 00 00 00 02 06 0F
                                 15 01 00 00 00 00 02 4B 00
                                 15 01 00 00 00 00 02 56 4A
                                 15 01 00 00 00 00 02 FE 00 
                                 15 01 00 00 00 00 02 C2 09 /*08 command  09 video*/
                                 15 01 00 00 00 00 02 35 00 
                                 15 01 00 00 00 00 02 FE 70 
                                 15 01 00 00 00 00 02 7D 61 
                                 15 01 00 00 00 00 02 7F 00 /*40:10bit 00 8bit*/
                                 15 01 00 00 00 00 02 7E 4E 
                                 15 01 00 00 00 00 02 52 2C 
                                 15 01 00 00 00 00 02 49 00 
                                 15 01 00 00 00 00 02 4A 00 
                                 15 01 00 00 00 00 02 4B 00 
                                 15 01 00 00 00 00 02 4C 00 
                                 15 01 00 00 00 00 02 4D E8 
                                 15 01 00 00 00 00 02 4E 25 
                                 15 01 00 00 00 00 02 4F 6E 
                                 15 01 00 00 00 00 02 50 AE 
                                 15 01 00 00 00 00 02 51 2F 
                                 15 01 00 00 00 00 02 AD F4 
                                 15 01 00 00 00 00 02 AE 8F 
                                 15 01 00 00 00 00 02 AF 00 
                                 15 01 00 00 00 00 02 B0 54 
                                 15 01 00 00 00 00 02 B1 3A      
                                 15 01 00 00 00 00 02 B2 00 
                                 15 01 00 00 00 00 02 B3 00 
                                 15 01 00 00 00 00 02 B4 00 
                                 15 01 00 00 00 00 02 B5 00 
                                 15 01 00 00 00 00 02 B6 18 
                                 15 01 00 00 00 00 02 B7 30 
                                 15 01 00 00 00 00 02 B8 4A 
                                 15 01 00 00 00 00 02 B9 98 
                                 15 01 00 00 00 00 02 BA 30 
                                 15 01 00 00 00 00 02 BB 60 
                                 15 01 00 00 00 00 02 BC 50 
                                 15 01 00 00 00 00 02 BD 00                            
                                 15 01 00 00 00 00 02 BE 00                            
                                 15 01 00 00 00 00 02 BF 39
                                 15 01 00 00 00 00 02 FE 00                            
                                 15 01 00 00 00 00 02 51 66   
				 05 01 00 00 78 00 02 11 00
				 05 01 00 00 14 00 02 29 00
						];
					};

					command@2 {
						shift,on-cmd-name = "natural";
						shift,on-cmd-state = "dsi_lp_mode";
						shift,on-cmd-command = [
                                 15 01 00 00 00 00 02 FE 40 
                                 15 01 00 00 00 00 02 05 04 
                                 15 01 00 00 00 00 02 06 08 
                                 15 01 00 00 00 00 02 08 04 
                                 15 01 00 00 00 00 02 09 08           
                                 15 01 00 00 00 00 02 0A 07 
                                 15 01 00 00 00 00 02 0B CC 
                                 15 01 00 00 00 00 02 0C 07 
                                 15 01 00 00 00 00 02 0D 90 
                                 15 01 00 00 00 00 02 0F 87 
                                 15 01 00 00 00 00 02 20 8D 
                                 15 01 00 00 00 00 02 21 8D 
                                 15 01 00 00 00 00 02 24 05 
                                 15 01 00 00 00 00 02 26 05 
                                 15 01 00 00 00 00 02 28 05 
                                 15 01 00 00 00 00 02 2A 05 
                                 15 01 00 00 00 00 02 2D 28 
                                 15 01 00 00 00 00 02 2F 28 
                                 15 01 00 00 00 00 02 30 32 
                                 15 01 00 00 00 00 02 31 32 
                                 15 01 00 00 00 00 02 37 80 
                                 15 01 00 00 00 00 02 38 30 
                                 15 01 00 00 00 00 02 39 A8     
                                 15 01 00 00 00 00 02 46 48
                                 15 01 00 00 00 00 02 47 48 
                                 15 01 00 00 00 00 02 6B 10  
                                 15 01 00 00 00 00 02 6F 02 
                                 15 01 00 00 00 00 02 74 2B /* (AVDD) 7.6V*/
                                 15 01 00 00 00 00 02 80 1A /* (OVSS)  -2.9V*/
                                 15 01 00 00 00 00 02 FE 40 
                                 15 01 00 00 00 00 02 93 10 
                                 15 01 00 00 00 00 02 16 00 
                                 15 01 00 00 00 00 02 85 07 
                                 15 01 00 00 00 00 02 84 01 
                                 15 01 00 00 00 00 02 86 0F 
                                 15 01 00 00 00 00 02 87 05 
                                 15 01 00 00 00 00 02 8C 00 
                                 15 01 00 00 00 00 02 88 2E 
                                 15 01 00 00 00 00 02 89 2E 
                                 15 01 00 00 00 00 02 8B 09 
                                 15 01 00 00 00 00 02 95 00 
                                 15 01 00 00 00 00 02 91 00 
                                 15 01 00 00 00 00 02 90 00 
                                 15 01 00 00 00 00 02 8D D0 
                                 15 01 00 00 00 00 02 8A 03 
                                 15 01 00 00 00 00 02 FE A0 
                                 15 01 00 00 00 00 02 13 00 
                                 15 01 00 00 00 00 02 33 00 
                                 15 01 00 00 00 00 02 0B 33 
                                 15 01 00 00 00 00 02 36 1E 
                                 15 01 00 00 00 00 02 31 88 
                                 15 01 00 00 00 00 02 32 88 
                                 15 01 00 00 00 00 02 37 F1 
                                 15 01 00 00 00 00 02 FE 50
                                 15 01 00 00 00 00 02 00 00 //R0
                                 15 01 00 00 00 00 02 01 00
                                 15 01 00 00 00 00 02 02 00
                                 15 01 00 00 00 00 02 03 EB
                                 15 01 00 00 00 00 02 04 00
                                 15 01 00 00 00 00 02 05 F8
                                 15 01 00 00 00 00 02 06 01
                                 15 01 00 00 00 00 02 07 2D
                                 15 01 00 00 00 00 02 08 01
                                 15 01 00 00 00 00 02 09 62
                                 15 01 00 00 00 00 02 0A 01
                                 15 01 00 00 00 00 02 0B 97
                                 15 01 00 00 00 00 02 0C 01
                                 15 01 00 00 00 00 02 0D BD
                                 15 01 00 00 00 00 02 0E 01
                                 15 01 00 00 00 00 02 0F F4
                                 15 01 00 00 00 00 02 10 02
                                 15 01 00 00 00 00 02 11 23
                                 15 01 00 00 00 00 02 12 02
                                 15 01 00 00 00 00 02 13 49
                                 15 01 00 00 00 00 02 14 02
                                 15 01 00 00 00 00 02 15 6E
                                 15 01 00 00 00 00 02 16 02
                                 15 01 00 00 00 00 02 17 AC
                                 15 01 00 00 00 00 02 18 02
                                 15 01 00 00 00 00 02 19 E4
                                 15 01 00 00 00 00 02 1A 03
                                 15 01 00 00 00 00 02 1B 1E
                                 15 01 00 00 00 00 02 1C 03
                                 15 01 00 00 00 00 02 1D 4D
                                 15 01 00 00 00 00 02 1E 03
                                 15 01 00 00 00 00 02 1F 80
                                 15 01 00 00 00 00 02 20 03
                                 15 01 00 00 00 00 02 21 B2
                                 15 01 00 00 00 00 02 22 03
                                 15 01 00 00 00 00 02 23 E4
                                 15 01 00 00 00 00 02 24 04
                                 15 01 00 00 00 00 02 25 18
                                 15 01 00 00 00 00 02 26 04
                                 15 01 00 00 00 00 02 27 31
                                 15 01 00 00 00 00 02 28 04
                                 15 01 00 00 00 00 02 29 50
                                 15 01 00 00 00 00 02 2A 04
                                 15 01 00 00 00 00 02 2B 65
                                 15 01 00 00 00 00 02 30 04
                                 15 01 00 00 00 00 02 31 80
                                 15 01 00 00 00 00 02 32 04
                                 15 01 00 00 00 00 02 33 9A
                                 15 01 00 00 00 00 02 34 04
                                 15 01 00 00 00 00 02 35 B1
                                 15 01 00 00 00 00 02 36 04
                                 15 01 00 00 00 00 02 37 D4
                                 15 01 00 00 00 00 02 38 04
                                 15 01 00 00 00 00 02 39 E8
                                 15 01 00 00 00 00 02 3A 04
                                 15 01 00 00 00 00 02 3B F6
                                 15 01 00 00 00 00 02 40 05
                                 15 01 00 00 00 00 02 41 0E
                                 15 01 00 00 00 00 02 42 05
                                 15 01 00 00 00 00 02 43 13
                                 15 01 00 00 00 00 02 44 05
                                 15 01 00 00 00 00 02 45 17
                                 15 01 00 00 00 00 02 46 00 //G0
                                 15 01 00 00 00 00 02 47 00
                                 15 01 00 00 00 00 02 48 01
                                 15 01 00 00 00 00 02 49 41
                                 15 01 00 00 00 00 02 4A 01
                                 15 01 00 00 00 00 02 4B 4A
                                 15 01 00 00 00 00 02 4C 01
                                 15 01 00 00 00 00 02 4D 6E
                                 15 01 00 00 00 00 02 4E 01
                                 15 01 00 00 00 00 02 4F 92
                                 15 01 00 00 00 00 02 50 01
                                 15 01 00 00 00 00 02 51 B6
                                 15 01 00 00 00 00 02 52 01
                                 15 01 00 00 00 00 02 53 D4
                                 15 01 00 00 00 00 02 58 02
                                 15 01 00 00 00 00 02 59 07
                                 15 01 00 00 00 00 02 5A 02
                                 15 01 00 00 00 00 02 5B 32
                                 15 01 00 00 00 00 02 5C 02
                                 15 01 00 00 00 00 02 5D 5A
                                 15 01 00 00 00 00 02 5E 02
                                 15 01 00 00 00 00 02 5F 7E
                                 15 01 00 00 00 00 02 60 02
                                 15 01 00 00 00 00 02 61 BF
                                 15 01 00 00 00 00 02 62 02
                                 15 01 00 00 00 00 02 63 F7
                                 15 01 00 00 00 00 02 64 03
                                 15 01 00 00 00 00 02 65 30
                                 15 01 00 00 00 00 02 66 03
                                 15 01 00 00 00 00 02 67 63
                                 15 01 00 00 00 00 02 68 03
                                 15 01 00 00 00 00 02 69 98
                                 15 01 00 00 00 00 02 6A 03
                                 15 01 00 00 00 00 02 6B D0
                                 15 01 00 00 00 00 02 6C 04
                                 15 01 00 00 00 00 02 6D 02
                                 15 01 00 00 00 00 02 6E 04
                                 15 01 00 00 00 00 02 6F 35
                                 15 01 00 00 00 00 02 70 04
                                 15 01 00 00 00 00 02 71 50
                                 15 01 00 00 00 00 02 72 04
                                 15 01 00 00 00 00 02 73 6C
                                 15 01 00 00 00 00 02 74 04
                                 15 01 00 00 00 00 02 75 82
                                 15 01 00 00 00 00 02 76 04
                                 15 01 00 00 00 00 02 77 A0
                                 15 01 00 00 00 00 02 78 04
                                 15 01 00 00 00 00 02 79 BA
                                 15 01 00 00 00 00 02 7A 04
                                 15 01 00 00 00 00 02 7B D4
                                 15 01 00 00 00 00 02 7C 04
                                 15 01 00 00 00 00 02 7D F3
                                 15 01 00 00 00 00 02 7E 05
                                 15 01 00 00 00 00 02 7F 09
                                 15 01 00 00 00 00 02 80 05
                                 15 01 00 00 00 00 02 81 19
                                 15 01 00 00 00 00 02 82 05
                                 15 01 00 00 00 00 02 83 2C
                                 15 01 00 00 00 00 02 84 05
                                 15 01 00 00 00 00 02 85 32
                                 15 01 00 00 00 00 02 86 05
                                 15 01 00 00 00 00 02 87 38
                                 15 01 00 00 00 00 02 88 00 //B0
                                 15 01 00 00 00 00 02 89 00
                                 15 01 00 00 00 00 02 8A 01
                                 15 01 00 00 00 00 02 8B 84
                                 15 01 00 00 00 00 02 8C 01
                                 15 01 00 00 00 00 02 8D 8D
                                 15 01 00 00 00 00 02 8E 01
                                 15 01 00 00 00 00 02 8F B0
                                 15 01 00 00 00 00 02 90 01
                                 15 01 00 00 00 00 02 91 D3
                                 15 01 00 00 00 00 02 92 01
                                 15 01 00 00 00 00 02 93 F6
                                 15 01 00 00 00 00 02 94 02
                                 15 01 00 00 00 00 02 95 13
                                 15 01 00 00 00 00 02 96 02
                                 15 01 00 00 00 00 02 97 4A
                                 15 01 00 00 00 00 02 98 02
                                 15 01 00 00 00 00 02 99 76
                                 15 01 00 00 00 00 02 9A 02
                                 15 01 00 00 00 00 02 9B A0
                                 15 01 00 00 00 00 02 9C 02
                                 15 01 00 00 00 00 02 9D C6
                                 15 01 00 00 00 00 02 9E 03
                                 15 01 00 00 00 00 02 9F 0F
                                 15 01 00 00 00 00 02 A4 03
                                 15 01 00 00 00 00 02 A5 4D
                                 15 01 00 00 00 00 02 A6 03
                                 15 01 00 00 00 00 02 A7 88
                                 15 01 00 00 00 00 02 AC 03
                                 15 01 00 00 00 00 02 AD C2
                                 15 01 00 00 00 00 02 AE 03
                                 15 01 00 00 00 00 02 AF FB
                                 15 01 00 00 00 00 02 B0 04
                                 15 01 00 00 00 00 02 B1 35
                                 15 01 00 00 00 00 02 B2 04
                                 15 01 00 00 00 00 02 B3 6C
                                 15 01 00 00 00 00 02 B4 04
                                 15 01 00 00 00 00 02 B5 A4
                                 15 01 00 00 00 00 02 B6 04
                                 15 01 00 00 00 00 02 B7 C3
                                 15 01 00 00 00 00 02 B8 04
                                 15 01 00 00 00 00 02 B9 E1
                                 15 01 00 00 00 00 02 BA 04
                                 15 01 00 00 00 00 02 BB F7
                                 15 01 00 00 00 00 02 BC 05
                                 15 01 00 00 00 00 02 BD 16
                                 15 01 00 00 00 00 02 BE 05
                                 15 01 00 00 00 00 02 BF 30
                                 15 01 00 00 00 00 02 C0 05
                                 15 01 00 00 00 00 02 C1 51
                                 15 01 00 00 00 00 02 C2 05
                                 15 01 00 00 00 00 02 C3 74
                                 15 01 00 00 00 00 02 C4 05
                                 15 01 00 00 00 00 02 C5 88
                                 15 01 00 00 00 00 02 C6 05
                                 15 01 00 00 00 00 02 C7 9B
                                 15 01 00 00 00 00 02 C8 05
                                 15 01 00 00 00 00 02 C9 B1
                                 15 01 00 00 00 00 02 CA 05
                                 15 01 00 00 00 00 02 CB B7
                                 15 01 00 00 00 00 02 CC 05
                                 15 01 00 00 00 00 02 CD C1
                                 15 01 00 00 00 00 02 CE 00
                                 15 01 00 00 00 00 02 CF D0
                                 15 01 00 00 00 00 02 D0 00
                                 15 01 00 00 00 00 02 D1 DE
                                 15 01 00 00 00 00 02 D2 01
                                 15 01 00 00 00 00 02 D3 2F
                                 15 01 00 00 00 00 02 D4 01
                                 15 01 00 00 00 00 02 D5 38
                                 15 01 00 00 00 00 02 D6 01
                                 15 01 00 00 00 00 02 D7 73
                                 15 01 00 00 00 00 02 D8 01
                                 15 01 00 00 00 00 02 D9 7C
                                 15 01 00 00 00 00 02 FE 60 
                                 15 01 00 00 00 00 02 00 CC 
                                 15 01 00 00 00 00 02 01 0F 
                                 15 01 00 00 00 00 02 02 FF 
                                 15 01 00 00 00 00 02 03 01 
                                 15 01 00 00 00 00 02 04 00 
                                 15 01 00 00 00 00 02 05 02 
                                 15 01 00 00 00 00 02 06 00 
                                 15 01 00 00 00 00 02 07 00 
                                 15 01 00 00 00 00 02 09 C4 
                                 15 01 00 00 00 00 02 0A 00 
                                 15 01 00 00 00 00 02 0B 04 
                                 15 01 00 00 00 00 02 0C 01 
                                 15 01 00 00 00 00 02 0D 00 
                                 15 01 00 00 00 00 02 0E 04 
                                 15 01 00 00 00 00 02 0F 00 
                                 15 01 00 00 00 00 02 10 71 
                                 15 01 00 00 00 00 02 12 C4 
                                 15 01 00 00 00 00 02 13 00 
                                 15 01 00 00 00 00 02 14 04 
                                 15 01 00 00 00 00 02 15 01 
                                 15 01 00 00 00 00 02 16 00 
                                 15 01 00 00 00 00 02 17 06 
                                 15 01 00 00 00 00 02 18 00 
                                 15 01 00 00 00 00 02 19 71 
                                 15 01 00 00 00 00 02 1B C4 
                                 15 01 00 00 00 00 02 1C 00 
                                 15 01 00 00 00 00 02 1D 02 
                                 15 01 00 00 00 00 02 1E 00 
                                 15 01 00 00 00 00 02 1F 00 
                                 15 01 00 00 00 00 02 20 08 
                                 15 01 00 00 00 00 02 21 66 
                                 15 01 00 00 00 00 02 22 B4 
                                 15 01 00 00 00 00 02 24 C4 
                                 15 01 00 00 00 00 02 25 00 
                                 15 01 00 00 00 00 02 26 02 
                                 15 01 00 00 00 00 02 27 00 
                                 15 01 00 00 00 00 02 28 00 
                                 15 01 00 00 00 00 02 29 07 
                                 15 01 00 00 00 00 02 2A 66 
                                 15 01 00 00 00 00 02 2B B4 
                                 15 01 00 00 00 00 02 2F C4 
                                 15 01 00 00 00 00 02 30 00 
                                 15 01 00 00 00 00 02 31 04 
                                 15 01 00 00 00 00 02 32 01 
                                 15 01 00 00 00 00 02 33 00 
                                 15 01 00 00 00 00 02 34 03 
                                 15 01 00 00 00 00 02 35 00 
                                 15 01 00 00 00 00 02 36 71 
                                 15 01 00 00 00 00 02 38 C4 
                                 15 01 00 00 00 00 02 39 00 
                                 15 01 00 00 00 00 02 3A 04 
                                 15 01 00 00 00 00 02 3B 01 
                                 15 01 00 00 00 00 02 3D 00 
                                 15 01 00 00 00 00 02 3F 05 
                                 15 01 00 00 00 00 02 40 00 
                                 15 01 00 00 00 00 02 41 71 
                                 15 01 00 00 00 00 02 83 CE 
                                 15 01 00 00 00 00 02 84 02 
                                 15 01 00 00 00 00 02 85 20 
                                 15 01 00 00 00 00 02 86 DC 
                                 15 01 00 00 00 00 02 87 00 
                                 15 01 00 00 00 00 02 88 04 
                                 15 01 00 00 00 00 02 89 00 
                                 15 01 00 00 00 00 02 8A BB 
                                 15 01 00 00 00 00 02 8B 80 
                                 15 01 00 00 00 00 02 C7 0E  
                                 15 01 00 00 00 00 02 C8 05 
                                 15 01 00 00 00 00 02 C9 1F 
                                 15 01 00 00 00 00 02 CA 06 
                                 15 01 00 00 00 00 02 CB 00 
                                 15 01 00 00 00 00 02 CC 03 
                                 15 01 00 00 00 00 02 CD 04 
                                 15 01 00 00 00 00 02 CE 1F 
                                 15 01 00 00 00 00 02 CF 1F 
                                 15 01 00 00 00 00 02 D0 1F 
                                 15 01 00 00 00 00 02 D1 1F 
                                 15 01 00 00 00 00 02 D2 1F 
                                 15 01 00 00 00 00 02 D3 1F 
                                 15 01 00 00 00 00 02 D4 1F 
                                 15 01 00 00 00 00 02 D5 1F 
                                 15 01 00 00 00 00 02 D6 1F 
                                 15 01 00 00 00 00 02 D7 17 
                                 15 01 00 00 00 00 02 D8 1F 
                                 15 01 00 00 00 00 02 D9 16 
                                 15 01 00 00 00 00 02 DA 1F 
                                 15 01 00 00 00 00 02 DB 0E  
                                 15 01 00 00 00 00 02 DC 01 
                                 15 01 00 00 00 00 02 DD 1F 
                                 15 01 00 00 00 00 02 DE 02 
                                 15 01 00 00 00 00 02 DF 00 
                                 15 01 00 00 00 00 02 E0 03 
                                 15 01 00 00 00 00 02 E1 04 
                                 15 01 00 00 00 00 02 E2 1F 
                                 15 01 00 00 00 00 02 E3 1F 
                                 15 01 00 00 00 00 02 E4 1F 
                                 15 01 00 00 00 00 02 E5 1F 
                                 15 01 00 00 00 00 02 E6 1F 
                                 15 01 00 00 00 00 02 E7 1F 
                                 15 01 00 00 00 00 02 E8 1F 
                                 15 01 00 00 00 00 02 E9 1F 
                                 15 01 00 00 00 00 02 EA 1F 
                                 15 01 00 00 00 00 02 EB 17    
                                 15 01 00 00 00 00 02 EC 1F 
                                 15 01 00 00 00 00 02 ED 16 
                                 15 01 00 00 00 00 02 EE 1F 
                                 15 01 00 00 00 00 02 EF 03 
                                 15 01 00 00 00 00 02 FE 70 
                                 15 01 00 00 00 00 02 5A 0B 
                                 15 01 00 00 00 00 02 5B 0B 
                                 15 01 00 00 00 00 02 5C 55 
                                 15 01 00 00 00 00 02 5D 24                         
                                 15 01 00 00 00 00 02 FE 90 
                                 15 01 00 00 00 00 02 12 24 
                                 15 01 00 00 00 00 02 13 49 
                                 15 01 00 00 00 00 02 14 92 
                                 15 01 00 00 00 00 02 15 86 
                                 15 01 00 00 00 00 02 16 61 
                                 15 01 00 00 00 00 02 17 18 
                                 15 01 00 00 00 00 02 18 24 
                                 15 01 00 00 00 00 02 19 49 
                                 15 01 00 00 00 00 02 1A 92 
                                 15 01 00 00 00 00 02 1B 86 
                                 15 01 00 00 00 00 02 1C 61 
                                 15 01 00 00 00 00 02 1D 18 
                                 15 01 00 00 00 00 02 1E 24 
                                 15 01 00 00 00 00 02 1F 49 
                                 15 01 00 00 00 00 02 20 92 
                                 15 01 00 00 00 00 02 21 86 
                                 15 01 00 00 00 00 02 22 61 
                                 15 01 00 00 00 00 02 23 18 
                                 15 01 00 00 00 00 02 FE 40 
                                 15 01 00 00 00 00 02 0E 10 
                                 15 01 00 00 00 00 02 FE A0
                                 15 01 00 00 00 00 02 04 80
                                 15 01 00 00 00 00 02 16 00
                                 15 01 00 00 00 00 02 26 10
                                 15 01 00 00 00 00 02 2F 37    
                                 15 01 00 00 00 00 02 FE D0
                                 15 01 00 00 00 00 02 06 0F
                                 15 01 00 00 00 00 02 4B 00
                                 15 01 00 00 00 00 02 56 4A
                                 15 01 00 00 00 00 02 FE 00 
                                 15 01 00 00 00 00 02 C2 09 /*08 command  09 video*/
                                 15 01 00 00 00 00 02 35 00 
                                 15 01 00 00 00 00 02 FE 70 
                                 15 01 00 00 00 00 02 7D 61 
                                 15 01 00 00 00 00 02 7F 00 /*40:10bit 00 8bit*/
                                 15 01 00 00 00 00 02 7E 4E 
                                 15 01 00 00 00 00 02 52 2C 
                                 15 01 00 00 00 00 02 49 00 
                                 15 01 00 00 00 00 02 4A 00 
                                 15 01 00 00 00 00 02 4B 00 
                                 15 01 00 00 00 00 02 4C 00 
                                 15 01 00 00 00 00 02 4D E8 
                                 15 01 00 00 00 00 02 4E 25 
                                 15 01 00 00 00 00 02 4F 6E 
                                 15 01 00 00 00 00 02 50 AE 
                                 15 01 00 00 00 00 02 51 2F 
                                 15 01 00 00 00 00 02 AD F4 
                                 15 01 00 00 00 00 02 AE 8F 
                                 15 01 00 00 00 00 02 AF 00 
                                 15 01 00 00 00 00 02 B0 54 
                                 15 01 00 00 00 00 02 B1 3A      
                                 15 01 00 00 00 00 02 B2 00 
                                 15 01 00 00 00 00 02 B3 00 
                                 15 01 00 00 00 00 02 B4 00 
                                 15 01 00 00 00 00 02 B5 00 
                                 15 01 00 00 00 00 02 B6 18 
                                 15 01 00 00 00 00 02 B7 30 
                                 15 01 00 00 00 00 02 B8 4A 
                                 15 01 00 00 00 00 02 B9 98 
                                 15 01 00 00 00 00 02 BA 30 
                                 15 01 00 00 00 00 02 BB 60 
                                 15 01 00 00 00 00 02 BC 50 
                                 15 01 00 00 00 00 02 BD 00                            
                                 15 01 00 00 00 00 02 BE 00                            
                                 15 01 00 00 00 00 02 BF 39
                                 15 01 00 00 00 00 02 FE 00                            
                                 15 01 00 00 00 00 02 51 66   
				 05 01 00 00 78 00 02 11 00
				 05 01 00 00 14 00 02 29 00
						];
					};
				};
			};
		};
	};
};
